# CY8C3246PVI_147 register map
File version: 0.1
Registers are 8-bit, read-write, no defined reset value unless marked. A register's access mark holds for its fields unless they carry their own. Offsets are from the block's base; [hi:lo] are bit positions; 'fields as' and 'values as' point back to an identical list.

## MY_TIMER
Base 0x00000000
0x6509 MY_TIMER_COUNTER 24-bit — UDB.A0 - Current Down Counter Value
0x6529 MY_TIMER_PERIOD 24-bit — UDB.D0 - Assigned Period
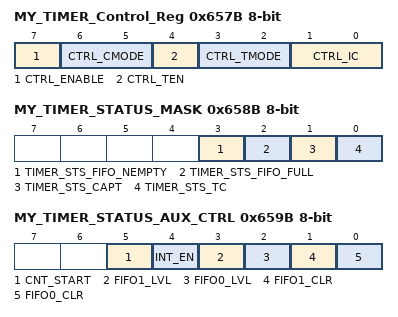
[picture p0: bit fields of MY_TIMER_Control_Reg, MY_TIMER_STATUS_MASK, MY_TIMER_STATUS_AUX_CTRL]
0x657B MY_TIMER_Control_Reg — UDB Control Register - Assigned Control Register Value
  [7] CTRL_ENABLE — Enable the Timer
  [6:5] CTRL_CMODE — Capture Mode
  [4] CTRL_TEN — Trigger Enable Bit
  [3:2] CTRL_TMODE — Trigger Mode
  [1:0] CTRL_IC — Interrupt Count
0x658B MY_TIMER_STATUS_MASK — UDB Status bits Interrupt Mask Enable Register
  [3] TIMER_STS_FIFO_NEMPTY ro — FIFO Empty status
  [2] TIMER_STS_FIFO_FULL ro — FIFO Full Status
  [1] TIMER_STS_CAPT ro — Enables the Interrupt on Capture
  [0] TIMER_STS_TC ro — Enables the Interrupt on TC
0x659B MY_TIMER_STATUS_AUX_CTRL — UDB Auxilliary Control Register
  [5] CNT_START — FIFO0 clear
    0=E_CNT_START0 (Disable counter); 1=E_CNT_START1 (Enable counter)
  [4] INT_EN
    0=E_INT_EN0 (Interrupt disabled); 1=E_INT_EN1 (Interrupt enabled)
  [3] FIFO1_LVL — FIFO level
    0=E_FIFO_LVL_0 (FIFO LVL: input mode: FIFO not full; output mode: FIFO not empty); 1=E_FIFO_LVL_1 (FIFO LVL: input mode: FIFO at least 1/2 empty; output mode: FIFO at least 1/2 full)
  [2] FIFO0_LVL — FIFO level
    values as FIFO1_LVL
  [1] FIFO1_CLR — FIFO1 clear
    0=E_FIFO_CLR_0 (Normal FIFO operation); 1=E_FIFO_CLR_1 (Clear FIFO state)
  [0] FIFO0_CLR — FIFO0 clear
    values as FIFO1_CLR

## FF_STATUS
Base 0x00006567
0x00 FF_STATUS_STATUS_REG
0x20 FF_STATUS_MASK_REG
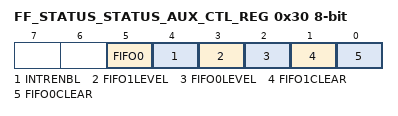
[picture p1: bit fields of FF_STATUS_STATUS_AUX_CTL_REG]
0x30 FF_STATUS_STATUS_AUX_CTL_REG
  [5] FIFO0 — FIFO0 clear
    1=ENABLED (Enable counter); 0=DISABLED (Disable counter)
  [4] INTRENBL — Enables or disables the Interrupt
    1=ENABLED (Interrupt enabled); 0=DISABLED (Interrupt disabled)
  [3] FIFO1LEVEL — FIFO level
    1=ENABLED (FIFO LVL: input mode: FIFO at least 1/2 empty; output mode: FIFO at least 1/2 full); 0=DISABLED (FIFO LVL: input mode: FIFO not full; output mode: FIFO not empty)
  [2] FIFO0LEVEL — FIFO level
    values as FIFO1LEVEL
  [1] FIFO1CLEAR — FIFO clear
    1=ENABLED (Clear FIFO state); 0=DISABLED (Normal FIFO operation)
  [0] FIFO0CLEAR — FIFO clear
    values as FIFO1CLEAR

## ADC_STATUS
Base 0x00006460
Registers as FF_STATUS (with FF_STATUS read as ADC_STATUS).

## WATCHDOG_COUNTER
Base 0x00000000
0x43A3 WATCHDOG_COUNTER_GLOBAL_ENABLE — PM.ACT.CFG
  [3:0] en_timer — Enable timer/counters.
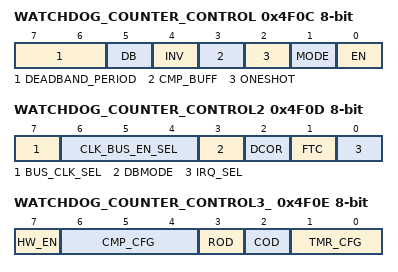
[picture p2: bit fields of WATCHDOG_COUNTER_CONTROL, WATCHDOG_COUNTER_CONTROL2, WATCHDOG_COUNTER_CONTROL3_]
0x4F0C WATCHDOG_COUNTER_CONTROL — TMRx.CFG0
  [7:6] DEADBAND_PERIOD
  [5] DB — Deadband mode--Deadband phases phi1 and phi2 are outputted on CMP and TC output pins respectively.
    0=Timer (CMP and TC are output.); 1=Deadband (PHI1 (instead of CMP) and PHI2 (instead of TC) are output.)
  [4] INV — Invert sense of TIMEREN signal
  [3] CMP_BUFF — Buffer compare register. Compare register updates only on timer terminal count.
  [2] ONESHOT — Timer stops upon reaching stop condition defined by TMR_CFG bits. Can be restarted by asserting TIMER RESET or disabling and re-enabling block.
  [1] MODE — Mode. (0 = Timer; 1 = Comparator)
    0=Timer mode. CNT/CMP register holds timer count value.; 1=Comparator mode. CNT/CMP register holds comparator threshold value.
  [0] EN — Enables timer/comparator.
0x4F0D WATCHDOG_COUNTER_CONTROL2 — TMRx.CFG1
  [7] BUS_CLK_SEL — Bus Clock selection.
  [6:4] CLK_BUS_EN_SEL — Digital Global Clock selection.
  [3] DBMODE — Deadband mode (asynchronous/synchronous). CMP output pin is also affected when not in deadband mode (CFG0.DEADBAND).
  [2] DCOR — Disable Clear on Read (DCOR) of Status Register SR0.
  [1] FTC — First Terminal Count (FTC). Setting this bit forces a single pulse on the TC pin when first enabled.
    0=Disable_FTC (Disable the single cycle pulse, which signifies the timer is starting.); 1=Enable_FTC (Enable the single cycle pulse, which signifies the timer is starting.)
  [0] IRQ_SEL — Irq selection. (0 = raw interrupts; 1 = status register interrupts)
0x4F0E WATCHDOG_COUNTER_CONTROL3_ — TMRx.CFG2
  [7] HW_EN — When set Timer Enable controls counting.
  [6:4] CMP_CFG — Comparator configurations
    0=Equal (Compare Equal); 1=Less_than (Compare Less Than); 2=Less_than_or_equal (Compare Less Than or Equal .); 3=Greater (Compare Greater Than .); 4=Greater_than_or_equal (Compare Greater Than or Equal)
  [3] ROD — Reset On Disable (ROD). Resets internal state of output logic
  [2] COD — Clear On Disable (COD). Clears or gates outputs to zero.
  [1:0] TMR_CFG — Timer configuration (MODE = 0): 000 = Continuous; 001 = Pulsewidth; 010 = Period; 011 = Stop on IRQ
    0=Continuous (Timer runs while EN bit of CFG0 register is set to '1'.); 1=Pulsewidth (Timer runs from positive to negative edge of TIMEREN.); 2=Period (Timer runs from positive to positive edge of TIMEREN.); 3=Irq (Timer runs until IRQ.)
0x4F10 WATCHDOG_COUNTER_PERIOD — TMRx.PER0 - Assigned Period
0x4F12 WATCHDOG_COUNTER_COUNTER — TMRx.CNT_CMP0 - Current Down Counter Value

## COUNTER_ENC
Base 0x00000000
0x6504 COUNTER_ENC_COUNTER — UDB.A0 - Current Counter Value
0x6524 COUNTER_ENC_PERIOD — UDB.D0 - Assigned Period
0x6534 COUNTER_ENC_COMPARE — UDB.D1 - Assigned Compare Value
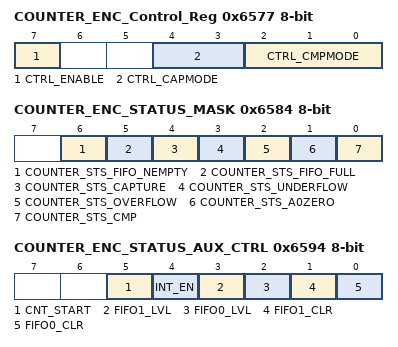
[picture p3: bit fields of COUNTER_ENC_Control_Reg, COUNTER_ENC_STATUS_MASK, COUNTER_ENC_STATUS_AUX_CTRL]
0x6577 COUNTER_ENC_Control_Reg — UDB Control Register - Assigned Control Register Value
  [7] CTRL_ENABLE — Enable Counter
  [4:3] CTRL_CAPMODE — Capture mode
  [2:0] CTRL_CMPMODE — Compare mode
0x6584 COUNTER_ENC_STATUS_MASK — UDB Status bits Interrupt Mask Enable Register
  [6] COUNTER_STS_FIFO_NEMPTY — FIFO Not Empty Status
  [5] COUNTER_STS_FIFO_FULL — FIFO Full Status
  [4] COUNTER_STS_CAPTURE — Capture Status
  [3] COUNTER_STS_UNDERFLOW — Underflow status
  [2] COUNTER_STS_OVERFLOW — Overflow status
  [1] COUNTER_STS_A0ZERO — A0 Zero ouput status
  [0] COUNTER_STS_CMP — Compare output status
0x6594 COUNTER_ENC_STATUS_AUX_CTRL — UDB Auxilliary Control Register
  [5] CNT_START — FIFO0 clear
    0=E_CNT_START0 (Disable counter); 1=E_CNT_START1 (Enable counter)
  [4] INT_EN
    0=E_INT_EN0 (Interrupt disabled); 1=E_INT_EN1 (Interrupt enabled)
  [3] FIFO1_LVL — FIFO level
    0=E_FIFO_LVL_0 (FIFO LVL: input mode: FIFO not full; output mode: FIFO not empty); 1=E_FIFO_LVL_1 (FIFO LVL: input mode: FIFO at least 1/2 empty; output mode: FIFO at least 1/2 full)
  [2] FIFO0_LVL — FIFO level
    values as FIFO1_LVL
  [1] FIFO1_CLR — FIFO1 clear
    0=E_FIFO_CLR_0 (Normal FIFO operation); 1=E_FIFO_CLR_1 (Clear FIFO state)
  [0] FIFO0_CLR — FIFO0 clear
    values as FIFO1_CLR

## UART_RS485 — UART
Base 0x00000000
0x642C RX_UART_RS485_RX_ADDRESS1 — RX Address1 Register
0x643C RX_UART_RS485_RX_ADDRESS2 — RX Address2 Register
0x6449 TX_UART_RS485_TX_DATA — TX Data Register
0x644C RX_UART_RS485_RX_DATA — RX Data Register
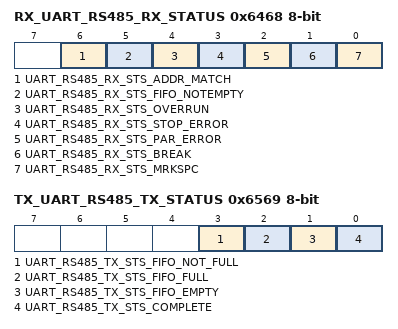
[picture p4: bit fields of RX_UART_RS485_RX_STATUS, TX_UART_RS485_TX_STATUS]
0x6468 RX_UART_RS485_RX_STATUS — RX status register
  [6] UART_RS485_RX_STS_ADDR_MATCH ro, [5] UART_RS485_RX_STS_FIFO_NOTEMPTY ro, [4] UART_RS485_RX_STS_OVERRUN ro, [3] UART_RS485_RX_STS_STOP_ERROR ro, [2] UART_RS485_RX_STS_PAR_ERROR ro, [1] UART_RS485_RX_STS_BREAK ro, [0] UART_RS485_RX_STS_MRKSPC ro
0x6569 TX_UART_RS485_TX_STATUS — TX status register
  [3] UART_RS485_TX_STS_FIFO_NOT_FULL ro, [2] UART_RS485_TX_STS_FIFO_FULL ro, [1] UART_RS485_TX_STS_FIFO_EMPTY ro, [0] UART_RS485_TX_STS_COMPLETE ro

## PWM_MOTORS
Base 0x00000000
0x6428 PWM_MOTORS__COMPARE1 — UDB.D0 - Assigned Compare1 Value
0x6438 PWM_MOTORS__COMPARE2 — UDB.D1 - Assigned Compare2 Value
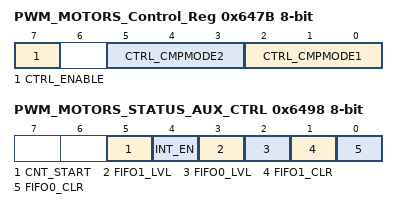
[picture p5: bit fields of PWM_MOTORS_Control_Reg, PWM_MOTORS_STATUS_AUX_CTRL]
0x647B PWM_MOTORS_Control_Reg — UDB Control Register - Assigned Control Register Value
  [7] CTRL_ENABLE — Enable the PWM
  [5:3] CTRL_CMPMODE2 — Compare mode 2
  [2:0] CTRL_CMPMODE1 — Compare mode 1
0x6498 PWM_MOTORS_STATUS_AUX_CTRL — UDB Auxilliary Control Register
  [5] CNT_START — FIFO0 clear
    0=E_CNT_START0 (Disable counter); 1=E_CNT_START1 (Enable counter)
  [4] INT_EN
    0=E_INT_EN0 (Interrupt disabled); 1=E_INT_EN1 (Interrupt enabled)
  [3] FIFO1_LVL — FIFO level
    0=E_FIFO_LVL_0 (FIFO LVL: input mode: FIFO not full; output mode: FIFO not empty); 1=E_FIFO_LVL_1 (FIFO LVL: input mode: FIFO at least 1/2 empty; output mode: FIFO at least 1/2 full)
  [2] FIFO0_LVL — FIFO level
    values as FIFO1_LVL
  [1] FIFO1_CLR — FIFO1 clear
    0=E_FIFO_CLR_0 (Normal FIFO operation); 1=E_FIFO_CLR_1 (Clear FIFO state)
  [0] FIFO0_CLR — FIFO0 clear
    values as FIFO1_CLR
